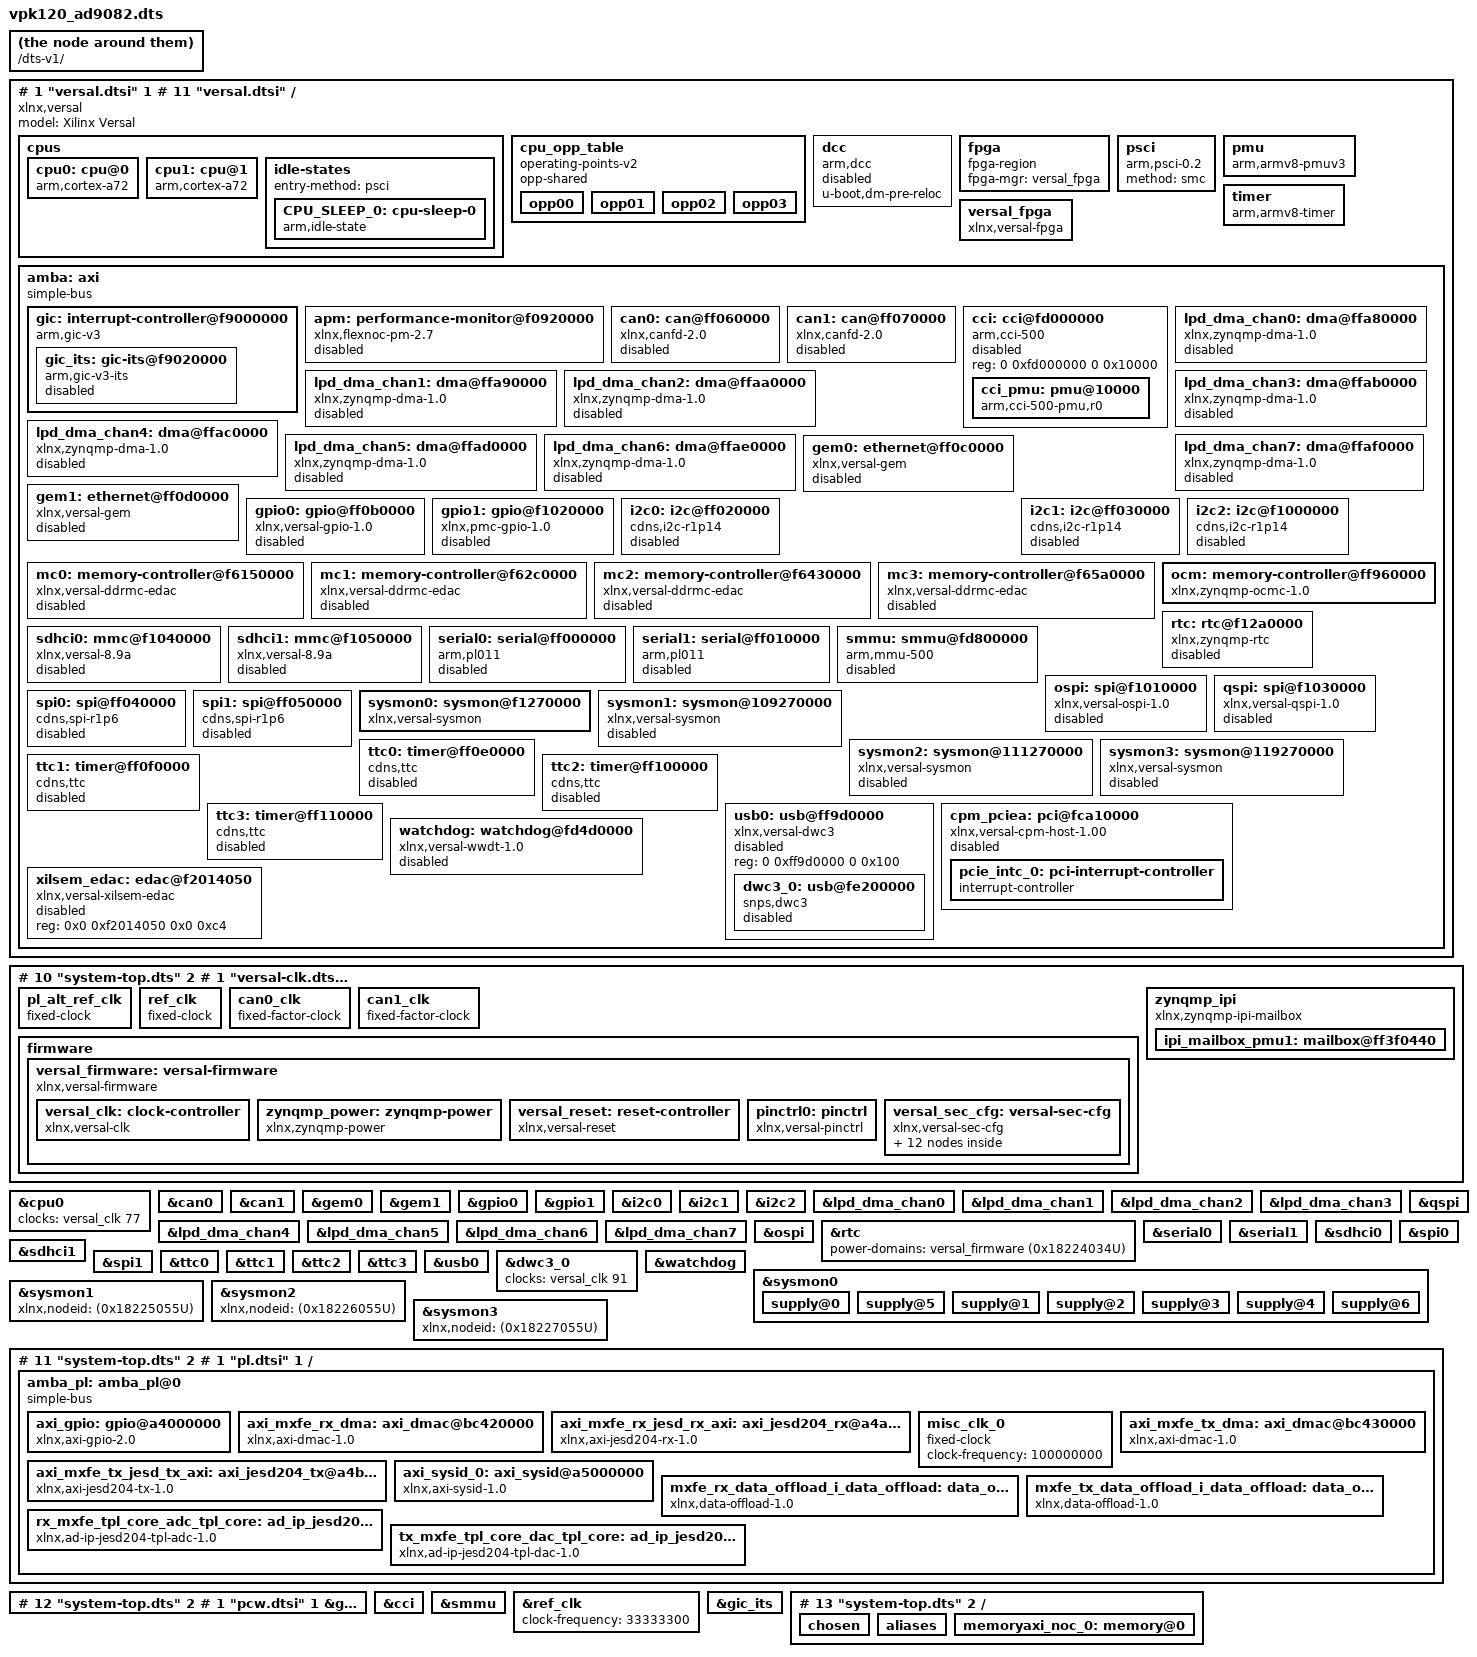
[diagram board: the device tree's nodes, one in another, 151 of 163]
# 0 "system-top.dts"
# 0 "<built-in>"
# 0 "<command-line>"
# 1 "system-top.dts"







/dts-v1/;
# 1 "versal.dtsi" 1
# 11 "versal.dtsi"
/ {
 compatible = "xlnx,versal";
 #address-cells = <2>;
 #size-cells = <2>;
 model = "Xilinx Versal";

 cpus: cpus {
  #address-cells = <1>;
  #size-cells = <0>;

  cpu0: cpu@0 {
   compatible = "arm,cortex-a72", "arm,armv8";
   device_type = "cpu";
   enable-method = "psci";
   operating-points-v2 = <&cpu_opp_table>;
   reg = <0>;
   cpu-idle-states = <&CPU_SLEEP_0>;
  };

  cpu1: cpu@1 {
   compatible = "arm,cortex-a72", "arm,armv8";
   device_type = "cpu";
   enable-method = "psci";
   operating-points-v2 = <&cpu_opp_table>;
   reg = <1>;
   cpu-idle-states = <&CPU_SLEEP_0>;
  };

  idle-states {
   entry-method = "psci";

   CPU_SLEEP_0: cpu-sleep-0 {
    compatible = "arm,idle-state";
    arm,psci-suspend-param = <0x40000000>;
    local-timer-stop;
    entry-latency-us = <300>;
    exit-latency-us = <600>;
    min-residency-us = <10000>;
   };
  };
 };

 cpu_opp_table: cpu_opp_table {
  compatible = "operating-points-v2";
  opp-shared;
  opp00 {
   opp-hz = /bits/ 64 <1199999988>;
   opp-microvolt = <1000000>;
   clock-latency-ns = <500000>;
  };
  opp01 {
   opp-hz = /bits/ 64 <599999994>;
   opp-microvolt = <1000000>;
   clock-latency-ns = <500000>;
  };
  opp02 {
   opp-hz = /bits/ 64 <399999996>;
   opp-microvolt = <1000000>;
   clock-latency-ns = <500000>;
  };
  opp03 {
   opp-hz = /bits/ 64 <299999997>;
   opp-microvolt = <1000000>;
   clock-latency-ns = <500000>;
  };
 };

 dcc: dcc {
  compatible = "arm,dcc";
  status = "disabled";
  u-boot,dm-pre-reloc;
 };

 fpga: fpga {
  compatible = "fpga-region";
  fpga-mgr = <&versal_fpga>;
  #address-cells = <2>;
  #size-cells = <2>;
 };

 psci: psci {
  compatible = "arm,psci-0.2";
  method = "smc";
 };

 pmu {
  compatible = "arm,armv8-pmuv3";
  interrupt-parent = <&gic>;
  interrupts = <1 7 0x304>;
 };

 timer: timer {
  compatible = "arm,armv8-timer";
  interrupt-parent = <&gic>;
  interrupts = <1 13 4>,
        <1 14 4>,
        <1 11 4>,
        <1 10 4>;
 };

 versal_fpga: versal_fpga {
  compatible = "xlnx,versal-fpga";
 };

 amba: axi {
  compatible = "simple-bus";
  #address-cells = <2>;
  #size-cells = <2>;
  ranges;
  interrupt-parent = <&gic>;
  u-boot,dm-pre-reloc;

  gic: interrupt-controller@f9000000 {
   compatible = "arm,gic-v3";
   #interrupt-cells = <3>;
   #address-cells = <2>;
   #size-cells = <2>;
   ranges;
   reg = <0 0xf9000000 0 0x80000>,
         <0 0xf9080000 0 0x80000>;
   interrupt-controller;
   interrupts = <1 9 4>;

   gic_its: gic-its@f9020000 {
    compatible = "arm,gic-v3-its";
    status = "disabled";
    msi-controller;
    msi-cells = <1>;
    reg = <0 0xf9020000 0 0x20000>;
   };
  };

  apm: performance-monitor@f0920000 {
   compatible = "xlnx,flexnoc-pm-2.7";
   status = "disabled";
   reg-names = "funnel", "baselpd", "basefpd";
   reg = <0x0 0xf0920000 0x0 0x1000>,
         <0x0 0xf0980000 0x0 0x9000>,
         <0x0 0xf0b80000 0x0 0x9000>;
  };

  can0: can@ff060000 {
   compatible = "xlnx,canfd-2.0";
   status = "disabled";
   reg = <0 0xff060000 0 0x6000>;
   interrupts = <0 20 4>;
   clock-names = "can_clk", "s_axi_aclk";
   rx-fifo-depth = <0x40>;
   tx-mailbox-count = <0x20>;
  };

  can1: can@ff070000 {
   compatible = "xlnx,canfd-2.0";
   status = "disabled";
   reg = <0 0xff070000 0 0x6000>;
   interrupts = <0 21 4>;
   clock-names = "can_clk", "s_axi_aclk";
   rx-fifo-depth = <0x40>;
   tx-mailbox-count = <0x20>;
  };

  cci: cci@fd000000 {
   compatible = "arm,cci-500";
   status = "disabled";
   reg = <0 0xfd000000 0 0x10000>;
   ranges = <0 0 0xfd000000 0xa0000>;
   #address-cells = <1>;
   #size-cells = <1>;
   cci_pmu: pmu@10000 {
    compatible = "arm,cci-500-pmu,r0";
    reg = <0x10000 0x90000>;
    interrupts = <0 106 4>,
          <0 106 4>,
          <0 106 4>,
          <0 106 4>,
          <0 106 4>,
          <0 106 4>,
          <0 106 4>,
          <0 106 4>,
          <0 106 4>;
   };
  };

  lpd_dma_chan0: dma@ffa80000 {
   compatible = "xlnx,zynqmp-dma-1.0";
   status = "disabled";
   reg = <0 0xffa80000 0 0x1000>;
   interrupts = <0 60 4>;
   clock-names = "clk_main", "clk_apb";

   xlnx,bus-width = <64>;

  };

  lpd_dma_chan1: dma@ffa90000 {
   compatible = "xlnx,zynqmp-dma-1.0";
   status = "disabled";
   reg = <0 0xffa90000 0 0x1000>;
   interrupts = <0 61 4>;
   clock-names = "clk_main", "clk_apb";

   xlnx,bus-width = <64>;

  };

  lpd_dma_chan2: dma@ffaa0000 {
   compatible = "xlnx,zynqmp-dma-1.0";
   status = "disabled";
   reg = <0 0xffaa0000 0 0x1000>;
   interrupts = <0 62 4>;
   clock-names = "clk_main", "clk_apb";

   xlnx,bus-width = <64>;

  };


  lpd_dma_chan3: dma@ffab0000 {
   compatible = "xlnx,zynqmp-dma-1.0";
   status = "disabled";
   reg = <0 0xffab0000 0 0x1000>;
   interrupts = <0 63 4>;
   clock-names = "clk_main", "clk_apb";

   xlnx,bus-width = <64>;

  };

  lpd_dma_chan4: dma@ffac0000 {
   compatible = "xlnx,zynqmp-dma-1.0";
   status = "disabled";
   reg = <0 0xffac0000 0 0x1000>;
   interrupts = <0 64 4>;
   clock-names = "clk_main", "clk_apb";

   xlnx,bus-width = <64>;

  };

  lpd_dma_chan5: dma@ffad0000 {
   compatible = "xlnx,zynqmp-dma-1.0";
   status = "disabled";
   reg = <0 0xffad0000 0 0x1000>;
   interrupts = <0 65 4>;
   clock-names = "clk_main", "clk_apb";

   xlnx,bus-width = <64>;

  };

  lpd_dma_chan6: dma@ffae0000 {
   compatible = "xlnx,zynqmp-dma-1.0";
   status = "disabled";
   reg = <0 0xffae0000 0 0x1000>;
   interrupts = <0 66 4>;
   clock-names = "clk_main", "clk_apb";

   xlnx,bus-width = <64>;

  };

  lpd_dma_chan7: dma@ffaf0000 {
   compatible = "xlnx,zynqmp-dma-1.0";
   status = "disabled";
   reg = <0 0xffaf0000 0 0x1000>;
   interrupts = <0 67 4>;
   clock-names = "clk_main", "clk_apb";

   xlnx,bus-width = <64>;

  };

  gem0: ethernet@ff0c0000 {
            compatible = "xlnx,versal-gem", "cdns,gem";
   status = "disabled";
   reg = <0 0xff0c0000 0 0x1000>;
   interrupts = <0 56 4>, <0 56 4>;
   clock-names = "pclk", "hclk", "tx_clk", "rx_clk", "tsu_clk";


   #address-cells = <1>;
   #size-cells = <0>;
  };

  gem1: ethernet@ff0d0000 {
            compatible = "xlnx,versal-gem", "cdns,gem";
   status = "disabled";
   reg = <0 0xff0d0000 0 0x1000>;
   interrupts = <0 58 4>, <0 58 4>;
   clock-names = "pclk", "hclk", "tx_clk", "rx_clk", "tsu_clk";


   #address-cells = <1>;
   #size-cells = <0>;
  };


  gpio0: gpio@ff0b0000 {
   compatible = "xlnx,versal-gpio-1.0";
   status = "disabled";
   reg = <0 0xff0b0000 0 0x1000>;
   interrupts = <0 13 4>;
   #gpio-cells = <2>;
   gpio-controller;
   #interrupt-cells = <2>;
   interrupt-controller;
  };

  gpio1: gpio@f1020000 {
   compatible = "xlnx,pmc-gpio-1.0";
   status = "disabled";
   reg = <0 0xf1020000 0 0x1000>;
   interrupts = <0 122 4>;
   #gpio-cells = <2>;
   gpio-controller;
   #interrupt-cells = <2>;
   interrupt-controller;
  };

  i2c0: i2c@ff020000 {
   compatible = "cdns,i2c-r1p14", "cdns,i2c-r1p10";
   status = "disabled";
   reg = <0 0xff020000 0 0x1000>;
   interrupts = <0 14 4>;
   clock-frequency = <100000>;
   #address-cells = <1>;
   #size-cells = <0>;
  };

  i2c1: i2c@ff030000 {
   compatible = "cdns,i2c-r1p14", "cdns,i2c-r1p10";
   status = "disabled";
   reg = <0 0xff030000 0 0x1000>;
   interrupts = <0 15 4>;
   clock-frequency = <100000>;
   #address-cells = <1>;
   #size-cells = <0>;
  };

  i2c2: i2c@f1000000 {
   compatible = "cdns,i2c-r1p14", "cdns,i2c-r1p10";
   status = "disabled";
   reg = <0 0xf1000000 0 0x1000>;
   interrupts = <0 123 4>;
   clock-frequency = <100000>;
   #address-cells = <1>;
   #size-cells = <0>;
  };

  mc0: memory-controller@f6150000 {
   compatible = "xlnx,versal-ddrmc-edac";
   status = "disabled";
   reg = <0x0 0xf6150000 0x0 0x2000>, <0x0 0xf6070000 0x0 0x20000>;
   reg-names = "ddrmc_base", "ddrmc_noc_base";
   interrupts = <0 147 4>;
   xlnx,mc-id = <0>;
  };

  mc1: memory-controller@f62c0000 {
   compatible = "xlnx,versal-ddrmc-edac";
   status = "disabled";
   reg = <0x0 0xf62c0000 0x0 0x2000>, <0x0 0xf6210000 0x0 0x20000>;
   reg-names = "ddrmc_base", "ddrmc_noc_base";
   interrupts = <0 147 4>;
   xlnx,mc-id = <1>;
  };

  mc2: memory-controller@f6430000 {
   compatible = "xlnx,versal-ddrmc-edac";
   status = "disabled";
   reg = <0x0 0xf6430000 0x0 0x2000>, <0x0 0xf6380000 0x0 0x20000>;
   reg-names = "ddrmc_base", "ddrmc_noc_base";
   interrupts = <0 147 4>;
   xlnx,mc-id = <2>;
  };

  mc3: memory-controller@f65a0000 {
   compatible = "xlnx,versal-ddrmc-edac";
   status = "disabled";
   reg = <0x0 0xf65a0000 0x0 0x2000>, <0x0 0xf64f0000 0x0 0x20000>;
   reg-names = "ddrmc_base", "ddrmc_noc_base";
   interrupts = <0 147 4>;
   xlnx,mc-id = <3>;
  };

  ocm: memory-controller@ff960000 {
   compatible = "xlnx,zynqmp-ocmc-1.0";
   reg = <0x0 0xff960000 0x0 0x1000>;
   interrupts = <0 10 4>;
  };

  rtc: rtc@f12a0000 {
   compatible = "xlnx,zynqmp-rtc";
   status = "disabled";
   reg = <0 0xf12a0000 0 0x100>;
   interrupt-names = "alarm", "sec";
   interrupts = <0 142 4>, <0 143 4>;
   calibration = <0x7FFF>;
  };

  sdhci0: mmc@f1040000 {
   compatible = "xlnx,versal-8.9a", "arasan,sdhci-8.9a";
   status = "disabled";
   reg = <0 0xf1040000 0 0x10000>;
   interrupts = <0 126 4>;
   clock-names = "clk_xin", "clk_ahb", "gate";
   #clock-cells = <1>;
   clock-output-names = "clk_out_sd0", "clk_in_sd0";


  };

  sdhci1: mmc@f1050000 {
   compatible = "xlnx,versal-8.9a", "arasan,sdhci-8.9a";
   status = "disabled";
   reg = <0 0xf1050000 0 0x10000>;
   interrupts = <0 128 4>;
   clock-names = "clk_xin", "clk_ahb", "gate";
   #clock-cells = <1>;
   clock-output-names = "clk_out_sd1", "clk_in_sd1";


  };

  serial0: serial@ff000000 {
   compatible = "arm,pl011", "arm,primecell";
   status = "disabled";
   reg = <0 0xff000000 0 0x1000>;
   interrupts = <0 18 4>;
   reg-io-width = <4>;
   clock-names = "uartclk", "apb_pclk";
   current-speed = <115200>;
   u-boot,dm-pre-reloc;
  };

  serial1: serial@ff010000 {
   compatible = "arm,pl011", "arm,primecell";
   status = "disabled";
   reg = <0 0xff010000 0 0x1000>;
   interrupts = <0 19 4>;
   reg-io-width = <4>;
   clock-names = "uartclk", "apb_pclk";
   current-speed = <115200>;
   u-boot,dm-pre-reloc;
  };

  smmu: smmu@fd800000 {
   compatible = "arm,mmu-500";
   status = "disabled";
   reg = <0 0xfd800000 0 0x40000>;
   stream-match-mask = <0x7c00>;
   #iommu-cells = <1>;
   #global-interrupts = <1>;
   interrupts = <0 107 4>,
         <0 107 4>, <0 107 4>, <0 107 4>, <0 107 4>,
         <0 107 4>, <0 107 4>, <0 107 4>, <0 107 4>,
         <0 107 4>, <0 107 4>, <0 107 4>, <0 107 4>,
         <0 107 4>, <0 107 4>, <0 107 4>, <0 107 4>,
         <0 107 4>, <0 107 4>, <0 107 4>, <0 107 4>,
         <0 107 4>, <0 107 4>, <0 107 4>, <0 107 4>,
         <0 107 4>, <0 107 4>, <0 107 4>, <0 107 4>,
         <0 107 4>, <0 107 4>, <0 107 4>, <0 107 4>;
  };

  ospi: spi@f1010000 {
   compatible = "xlnx,versal-ospi-1.0", "cadence,qspi", "cdns,qspi-nor";
   status = "disabled";
   reg = <0 0xf1010000 0 0x10000 0 0xc0000000 0 0x20000000>;
   interrupts = <0 124 4>, <0 124 4>;
   cdns,fifo-depth = <256>;
   cdns,fifo-width = <4>;
   cdns,is-dma = <1>;
   cdns,trigger-address = <0xC0000000>;
   #address-cells = <1>;
   #size-cells = <0>;
  };

  qspi: spi@f1030000 {
   compatible = "xlnx,versal-qspi-1.0";
   status = "disabled";
   reg = <0 0xf1030000 0 0x1000>;
   interrupts = <0 125 4>, <0 125 4>;
   clock-names = "ref_clk", "pclk";


   #address-cells = <1>;
   #size-cells = <0>;
  };


  spi0: spi@ff040000 {
   compatible = "cdns,spi-r1p6";
   status = "disabled";
   reg = <0 0xff040000 0 0x1000>;
   interrupts = <0 16 4>;
   clock-names = "ref_clk", "pclk";
   #address-cells = <1>;
   #size-cells = <0>;
  };

  spi1: spi@ff050000 {
   compatible = "cdns,spi-r1p6";
   status = "disabled";
   reg = <0 0xff050000 0 0x1000>;
   interrupts = <0 17 4>;
   clock-names = "ref_clk", "pclk";
   #address-cells = <1>;
   #size-cells = <0>;
  };

  sysmon0: sysmon@f1270000 {
   compatible = "xlnx,versal-sysmon";
   reg = <0x0 0xf1270000 0x0 0x4000>;
   interrupts = <0 144 4>;
   xlnx,numchannels = /bits/8 <0>;
  };

  sysmon1: sysmon@109270000 {
   compatible = "xlnx,versal-sysmon";
   #address-cells = <2>;
   #size-cells = <2>;
   status = "disabled";
   reg = <0x1 0x09270000 0x0 0x4000>;
   xlnx,numchannels = /bits/8 <0>;
  };

  sysmon2: sysmon@111270000 {
   compatible = "xlnx,versal-sysmon";
   #address-cells = <2>;
   #size-cells = <2>;
   status = "disabled";
   reg = <0x1 0x11270000 0x0 0x4000>;
   xlnx,numchannels = /bits/8 <0>;
  };

  sysmon3: sysmon@119270000 {
   compatible = "xlnx,versal-sysmon";
   #address-cells = <2>;
   #size-cells = <2>;
   status = "disabled";
   reg = <0x1 0x19270000 0x0 0x4000>;
   xlnx,numchannels = /bits/8 <0>;
  };

  ttc0: timer@ff0e0000 {
   compatible = "cdns,ttc";
   status = "disabled";
   interrupts = <0 37 4>, <0 38 4>, <0 39 4>;
   reg = <0x0 0xff0e0000 0x0 0x1000>;
   timer-width = <32>;
  };

  ttc1: timer@ff0f0000 {
   compatible = "cdns,ttc";
   status = "disabled";
   interrupts = <0 40 4>, <0 41 4>, <0 42 4>;
   reg = <0x0 0xff0f0000 0x0 0x1000>;
   timer-width = <32>;
  };

  ttc2: timer@ff100000 {
   compatible = "cdns,ttc";
   status = "disabled";
   interrupts = <0 43 4>, <0 44 4>, <0 45 4>;
   reg = <0x0 0xff100000 0x0 0x1000>;
   timer-width = <32>;
  };

  ttc3: timer@ff110000 {
   compatible = "cdns,ttc";
   status = "disabled";
   interrupts = <0 46 4>, <0 47 4>, <0 48 4>;
   reg = <0x0 0xff110000 0x0 0x1000>;
   timer-width = <32>;
  };

  usb0: usb@ff9d0000 {
   compatible = "xlnx,versal-dwc3";
   status = "disabled";
   reg = <0 0xff9d0000 0 0x100>;
   clock-names = "bus_clk", "ref_clk";
   ranges;
   #address-cells = <2>;
   #size-cells = <2>;

   dwc3_0: usb@fe200000 {
    compatible = "snps,dwc3";
    status = "disabled";
    reg = <0 0xfe200000 0 0x10000>;
    interrupt-names = "dwc_usb3", "otg", "usb-wakeup";
    interrupts = <0 0x16 4>, <0 0x1A 4>, <0x0 0x4a 0x4>;

    snps,dis_u2_susphy_quirk;
    snps,dis_u3_susphy_quirk;
    snps,quirk-frame-length-adjustment = <0x20>;
    clock-names = "ref";

   };
  };

  cpm_pciea: pci@fca10000 {
   #address-cells = <3>;
   #interrupt-cells = <1>;
   #size-cells = <2>;
   compatible = "xlnx,versal-cpm-host-1.00";
   status = "disabled";
   interrupt-map = <0 0 0 1 &pcie_intc_0 0>,
     <0 0 0 2 &pcie_intc_0 1>,
     <0 0 0 3 &pcie_intc_0 2>,
     <0 0 0 4 &pcie_intc_0 3>;
   interrupt-map-mask = <0 0 0 7>;
   interrupt-names = "misc";
   interrupts = <0 72 4>;
   ranges = <0x02000000 0x00000000 0xe0000000 0x0 0xe0000000 0x00000000 0x10000000>,
     <0x43000000 0x00000080 0x00000000 0x00000080 0x00000000 0x00000000 0x80000000>;
   msi-map = <0x0 &gic_its 0x0 0x10000>;
   reg = <0x0 0xfca10000 0x0 0x1000>,
         <0x6 0x00000000 0x0 0x1000000>;
   reg-names = "cpm_slcr", "cfg";
   pcie_intc_0: pci-interrupt-controller {
    #address-cells = <0>;
    #interrupt-cells = <1>;
    interrupt-controller ;
   };
  };

  watchdog: watchdog@fd4d0000 {
   compatible = "xlnx,versal-wwdt-1.0";
   status = "disabled";
   reg = <0 0xfd4d0000 0 0x10000>;
   interrupt-names = "wdt", "wwdt_reset_pending";
   interrupts = <0 0x64 1>, <0 0x6D 1>;
   timeout-sec = <30>;
   pretimeout-sec = <25>;
  };
  xilsem_edac: edac@f2014050 {
   compatible = "xlnx,versal-xilsem-edac";
   status = "disabled";
   reg = <0x0 0xf2014050 0x0 0xc4>;
  };
 };

};
# 10 "system-top.dts" 2
# 1 "versal-clk.dtsi" 1
# 10 "versal-clk.dtsi"
# 1 "include/dt-bindings/clock/xlnx-versal-clk.h" 1
# 11 "versal-clk.dtsi" 2
# 1 "include/dt-bindings/power/xlnx-versal-power.h" 1
# 12 "versal-clk.dtsi" 2
# 1 "include/dt-bindings/power/xlnx-versal-regnode.h" 1
# 13 "versal-clk.dtsi" 2
# 1 "include/dt-bindings/reset/xlnx-versal-resets.h" 1
# 14 "versal-clk.dtsi" 2
/ {
 pl_alt_ref_clk: pl_alt_ref_clk {
  u-boot,dm-pre-reloc;
  compatible = "fixed-clock";
  #clock-cells = <0>;
  clock-frequency = <33333333>;
 };

 ref_clk: ref_clk {
  u-boot,dm-pre-reloc;
  compatible = "fixed-clock";
  #clock-cells = <0>;
  clock-frequency = <33333333>;
 };

 can0_clk: can0_clk {
  #clock-cells = <0>;
  compatible = "fixed-factor-clock";
  clocks = <&versal_clk 96>;
  clock-div = <2>;
  clock-mult = <1>;
 };

 can1_clk: can1_clk {
  #clock-cells = <0>;
  compatible = "fixed-factor-clock";
  clocks = <&versal_clk 97>;
  clock-div = <2>;
  clock-mult = <1>;
 };

 firmware {
  versal_firmware: versal-firmware {
   compatible = "xlnx,versal-firmware";
   interrupt-parent = <&gic>;
   u-boot,dm-pre-reloc;
   method = "smc";
   #power-domain-cells = <1>;

   versal_clk: clock-controller {
    u-boot,dm-pre-reloc;
    #clock-cells = <1>;
    compatible = "xlnx,versal-clk";
    clocks = <&ref_clk>, <&pl_alt_ref_clk>;
    clock-names = "ref_clk", "pl_alt_ref_clk";
   };

   zynqmp_power: zynqmp-power {
    compatible = "xlnx,zynqmp-power";
    interrupt-parent = <&gic>;
    interrupts = <0 30 4>;
    mboxes = <&ipi_mailbox_pmu1 0>,
      <&ipi_mailbox_pmu1 1>;
    mbox-names = "tx", "rx";
   };
   versal_reset: reset-controller {
    compatible = "xlnx,versal-reset";
    #reset-cells = <1>;
   };

   pinctrl0: pinctrl {
    compatible = "xlnx,versal-pinctrl";
   };

   versal_sec_cfg: versal-sec-cfg {
    compatible = "xlnx,versal-sec-cfg";
    #address-cells = <1>;
    #size-cells = <1>;

    bbram_zeroize: bbram-zeroize@4 {
     reg = <0x04 0x4>;
    };

    bbram_key: bbram-key@10 {
     reg = <0x10 0x20>;
    };

    bbram_usr: bbram-usr@30 {
     reg = <0x30 0x4>;
    };

    bbram_lock: bbram-lock@48 {
     reg = <0x48 0x4>;
    };

    user_key0: user-key@110 {
     reg = <0x110 0x20>;
    };

    user_key1: user-key@130 {
     reg = <0x130 0x20>;
    };

    user_key2: user-key@150 {
     reg = <0x150 0x20>;
    };

    user_key3: user-key@170 {
     reg = <0x170 0x20>;
    };

    user_key4: user-key@190 {
     reg = <0x190 0x20>;
    };

    user_key5: user-key@1b0 {
     reg = <0x1b0 0x20>;
    };

    user_key6: user-key@1d0 {
     reg = <0x1d0 0x20>;
    };

    user_key7: user-key@1f0 {
     reg = <0x1f0 0x20>;
    };
   };
  };
 };

 zynqmp_ipi {
  compatible = "xlnx,zynqmp-ipi-mailbox";
  interrupt-parent = <&gic>;
  interrupts = <0 30 4>;
  xlnx,ipi-id = <2>;
  #address-cells = <2>;
  #size-cells = <2>;
  ranges;

  ipi_mailbox_pmu1: mailbox@ff3f0440 {
   reg = <0 0xff3f0440 0 0x20>,
         <0 0xff3f0460 0 0x20>,
         <0 0xff3f0280 0 0x20>,
         <0 0xff3f02a0 0 0x20>;
   reg-names = "local_request_region", "local_response_region",
        "remote_request_region", "remote_response_region";
   #mbox-cells = <1>;
   xlnx,ipi-id = <1>;
  };
 };
};

&cpu0 {
 clocks = <&versal_clk 77>;
};

&can0 {
 clocks = <&can0_clk>, <&versal_clk 82>;
 power-domains = <&versal_firmware (0x1822401fU)>;
};

&can1 {
 clocks = <&can1_clk>, <&versal_clk 82>;
 power-domains = <&versal_firmware (0x18224020U)>;
};

&gem0 {
 clocks = <&versal_clk 82>, <&versal_clk 88>, <&versal_clk 49>, <&versal_clk 48>, <&versal_clk 43>;
 power-domains = <&versal_firmware (0x18224019U)>;
};

&gem1 {
 clocks = <&versal_clk 82>, <&versal_clk 89>, <&versal_clk 51>, <&versal_clk 50>, <&versal_clk 43>;
 power-domains = <&versal_firmware (0x1822401aU)>;
};

&gpio0 {
 clocks = <&versal_clk 82>;
 power-domains = <&versal_firmware (0x18224023U)>;
};

&gpio1 {
 clocks = <&versal_clk 61>;
 power-domains = <&versal_firmware (0x1822402cU)>;
};

&i2c0 {
 clocks = <&versal_clk 98>;
 power-domains = <&versal_firmware (0x1822401dU)>;
};

&i2c1 {
 clocks = <&versal_clk 99>;
 power-domains = <&versal_firmware (0x1822401eU)>;
};

&i2c2 {
 clocks = <&versal_clk 62>;
 power-domains = <&versal_firmware (0x1822402dU)>;
};

&lpd_dma_chan0 {
 clocks = <&versal_clk 81>, <&versal_clk 82>;
 power-domains = <&versal_firmware (0x18224035U)>;
};

&lpd_dma_chan1 {
 clocks = <&versal_clk 81>, <&versal_clk 82>;
 power-domains = <&versal_firmware (0x18224036U)>;
};

&lpd_dma_chan2 {
 clocks = <&versal_clk 81>, <&versal_clk 82>;
 power-domains = <&versal_firmware (0x18224037U)>;
};

&lpd_dma_chan3 {
 clocks = <&versal_clk 81>, <&versal_clk 82>;
 power-domains = <&versal_firmware (0x18224038U)>;
};

&lpd_dma_chan4 {
 clocks = <&versal_clk 81>, <&versal_clk 82>;
 power-domains = <&versal_firmware (0x18224039U)>;
};

&lpd_dma_chan5 {
 clocks = <&versal_clk 81>, <&versal_clk 82>;
 power-domains = <&versal_firmware (0x1822403aU)>;
};

&lpd_dma_chan6 {
 clocks = <&versal_clk 81>, <&versal_clk 82>;
 power-domains = <&versal_firmware (0x1822403bU)>;
};

&lpd_dma_chan7 {
 clocks = <&versal_clk 81>, <&versal_clk 82>;
 power-domains = <&versal_firmware (0x1822403cU)>;
};

&qspi {
 clocks = <&versal_clk 57>, <&versal_clk 82>;
 power-domains = <&versal_firmware (0x1822402bU)>;
};

&ospi {
 clocks = <&versal_clk 58>;
 power-domains = <&versal_firmware (0x1822402aU)>;
 reset-names = "qspi";
 resets = <&versal_reset (0xc10402eU)>;
};

&rtc {
 power-domains = <&versal_firmware (0x18224034U)>;
};

&serial0 {
 clocks = <&versal_clk 92>, <&versal_clk 82>;
 power-domains = <&versal_firmware (0x18224021U)>;
};

&serial1 {
 clocks = <&versal_clk 93>, <&versal_clk 82>;
 power-domains = <&versal_firmware (0x18224022U)>;
};

&sdhci0 {
 clocks = <&versal_clk 59>, <&versal_clk 82>,
  <&versal_clk 74>;
 power-domains = <&versal_firmware (0x1822402eU)>;
};

&sdhci1 {
 clocks = <&versal_clk 60>, <&versal_clk 82>,
  <&versal_clk 74>;
 power-domains = <&versal_firmware (0x1822402fU)>;
};

&spi0 {
 clocks = <&versal_clk 94>, <&versal_clk 82>;
 power-domains = <&versal_firmware (0x1822401bU)>;
};

&spi1 {
 clocks = <&versal_clk 95>, <&versal_clk 82>;
 power-domains = <&versal_firmware (0x1822401cU)>;
};

&ttc0 {
 clocks = <&versal_clk 39>, <&versal_clk 82>;
 power-domains = <&versal_firmware (0x18224024U)>;
};

&ttc1 {
 clocks = <&versal_clk 40>, <&versal_clk 82>;
 power-domains = <&versal_firmware (0x18224025U)>;
};

&ttc2 {
 clocks = <&versal_clk 41>, <&versal_clk 82>;
 power-domains = <&versal_firmware (0x18224026U)>;
};

&ttc3 {
 clocks = <&versal_clk 42>, <&versal_clk 82>;
 power-domains = <&versal_firmware (0x18224027U)>;
};

&usb0 {
 clocks = <&versal_clk 91>, <&versal_clk 104>;
 power-domains = <&versal_firmware (0x18224018U)>;
 resets = <&versal_reset (0xc104036U)>;
};

&dwc3_0 {
 clocks = <&versal_clk 91>;
};

&watchdog {
 clocks = <&versal_clk 82>;
 power-domains = <&versal_firmware (0x18224029U)>;
};

&sysmon0 {
 xlnx,nodeid = <(0x18224055U)>;
};

&sysmon1 {
 xlnx,nodeid = <(0x18225055U)>;
};

&sysmon2 {
 xlnx,nodeid = <(0x18226055U)>;
};

&sysmon3 {
 xlnx,nodeid = <(0x18227055U)>;
};
# 11 "system-top.dts" 2
# 1 "pl.dtsi" 1







/ {
 amba_pl: amba_pl@0 {
  #address-cells = <2>;
  #size-cells = <2>;
  compatible = "simple-bus";
  ranges ;
  axi_gpio: gpio@a4000000 {
   #gpio-cells = <2>;
   #interrupt-cells = <2>;
   clock-names = "s_axi_aclk";
   clocks = <&versal_clk 65>;
   compatible = "xlnx,axi-gpio-2.0", "xlnx,xps-gpio-1.00.a";
   gpio-controller ;
   interrupt-controller ;
   interrupt-names = "ip2intc_irpt";
   interrupt-parent = <&gic>;
   interrupts = <0 84 4>;
   reg = <0x0 0xa4000000 0x0 0x1000>;
   xlnx,all-inputs = <0x0>;
   xlnx,all-inputs-2 = <0x0>;
   xlnx,all-outputs = <0x0>;
   xlnx,all-outputs-2 = <0x0>;
   xlnx,dout-default = <0x00000000>;
   xlnx,dout-default-2 = <0x00000000>;
   xlnx,gpio-width = <0x20>;
   xlnx,gpio2-width = <0x20>;
   xlnx,interrupt-present = <0x1>;
   xlnx,is-dual = <0x1>;
   xlnx,tri-default = <0xFFFFFFFF>;
   xlnx,tri-default-2 = <0xFFFFFFFF>;
  };
  axi_mxfe_rx_dma: axi_dmac@bc420000 {

   clock-names = "s_axi_aclk", "m_dest_axi_aclk", "s_axis_aclk";
   clocks = <&versal_clk 65>, <&versal_clk 66>, <&versal_clk 66>;
   compatible = "xlnx,axi-dmac-1.0";
   interrupt-names = "irq";
   interrupt-parent = <&gic>;
   interrupts = <0 97 4>;
   reg = <0x0 0xbc420000 0x0 0x1000>;
  };
  axi_mxfe_rx_jesd_rx_axi: axi_jesd204_rx@a4a90000 {

   clock-names = "s_axi_aclk", "core_clk";
   clocks = <&versal_clk 65>, <&misc_clk_0>;
   compatible = "xlnx,axi-jesd204-rx-1.0";
   interrupt-names = "irq";
   interrupt-parent = <&gic>;
   interrupts = <0 95 4>;
   reg = <0x0 0xa4a90000 0x0 0x4000>;
  };
  misc_clk_0: misc_clk_0 {
   #clock-cells = <0>;
   clock-frequency = <100000000>;
   compatible = "fixed-clock";
  };
  axi_mxfe_tx_dma: axi_dmac@bc430000 {

   clock-names = "s_axi_aclk", "m_src_axi_aclk", "m_axis_aclk";
   clocks = <&versal_clk 65>, <&versal_clk 66>, <&versal_clk 66>;
   compatible = "xlnx,axi-dmac-1.0";
   interrupt-names = "irq";
   interrupt-parent = <&gic>;
   interrupts = <0 96 4>;
   reg = <0x0 0xbc430000 0x0 0x1000>;
  };
  axi_mxfe_tx_jesd_tx_axi: axi_jesd204_tx@a4b90000 {

   clock-names = "s_axi_aclk", "core_clk";
   clocks = <&versal_clk 65>, <&misc_clk_0>;
   compatible = "xlnx,axi-jesd204-tx-1.0";
   interrupt-names = "irq";
   interrupt-parent = <&gic>;
   interrupts = <0 94 4>;
   reg = <0x0 0xa4b90000 0x0 0x4000>;
  };
  axi_sysid_0: axi_sysid@a5000000 {

   clock-names = "s_axi_aclk";
   clocks = <&versal_clk 65>;
   compatible = "xlnx,axi-sysid-1.0";
   reg = <0x0 0xa5000000 0x0 0x10000>;
  };
  mxfe_rx_data_offload_i_data_offload: data_offload@bc450000 {

   clock-names = "s_axi_aclk", "s_axis_aclk", "m_axis_aclk";
   clocks = <&versal_clk 65>, <&misc_clk_0>, <&versal_clk 66>;
   compatible = "xlnx,data-offload-1.0";
   reg = <0x0 0xbc450000 0x0 0x10000>;
  };
  mxfe_tx_data_offload_i_data_offload: data_offload@bc440000 {

   clock-names = "s_axi_aclk", "s_axis_aclk", "m_axis_aclk";
   clocks = <&versal_clk 65>, <&versal_clk 66>, <&misc_clk_0>;
   compatible = "xlnx,data-offload-1.0";
   reg = <0x0 0xbc440000 0x0 0x10000>;
  };
  rx_mxfe_tpl_core_adc_tpl_core: ad_ip_jesd204_tpl_adc@a4a10000 {

   clock-names = "link_clk", "s_axi_aclk";
   clocks = <&misc_clk_0>, <&versal_clk 65>;
   compatible = "xlnx,ad-ip-jesd204-tpl-adc-1.0";
   reg = <0x0 0xa4a10000 0x0 0x2000>;
  };
  tx_mxfe_tpl_core_dac_tpl_core: ad_ip_jesd204_tpl_dac@a4b10000 {

   clock-names = "link_clk", "s_axi_aclk";
   clocks = <&misc_clk_0>, <&versal_clk 65>;
   compatible = "xlnx,ad-ip-jesd204-tpl-dac-1.0";
   reg = <0x0 0xa4b10000 0x0 0x2000>;
  };
 };
};
# 12 "system-top.dts" 2
# 1 "pcw.dtsi" 1







&gic {
 num_cpus = <2>;
 num_interrupts = <96>;
};
&lpd_dma_chan0 {
 status = "okay";
};
&lpd_dma_chan1 {
 status = "okay";
};
&lpd_dma_chan2 {
 status = "okay";
};
&lpd_dma_chan3 {
 status = "okay";
};
&lpd_dma_chan4 {
 status = "okay";
};
&lpd_dma_chan5 {
 status = "okay";
};
&lpd_dma_chan6 {
 status = "okay";
};
&lpd_dma_chan7 {
 status = "okay";
};
&gem0 {
 phy-mode = "rgmii-id";
 status = "okay";
};
&cci {
 status = "okay";
};
&smmu {
 status = "okay";
};
&i2c0 {
 clock-frequency = <400000>;
 status = "okay";
};
&i2c1 {
 clock-frequency = <400000>;
 status = "okay";
};
&gpio1 {
 status = "okay";
};
&qspi {
 is-dual = <1>;
 num-cs = <2>;
 spi-rx-bus-width = <4>;
 spi-tx-bus-width = <4>;
 status = "okay";
};
&rtc {
 status = "okay";
};
&sdhci1 {
 clock-frequency = <199999802>;
 status = "okay";
 xlnx,mio-bank = <0x1>;
};
&sysmon0 {
 #address-cells = <2>;
 #size-cells = <2>;
 xlnx,num-of-slr = <1>;
 xlnx,numchannels = /bits/8 <7>;
 xlnx,ssit-device = <0x0>;
 supply@0 {
  reg = <0>;
  xlnx,name = "vccaux";
 };
 supply@5 {
  reg = <5>;
  xlnx,name = "vcc_soc";
 };
 supply@1 {
  reg = <1>;
  xlnx,name = "vccaux_pmc";
 };
 supply@2 {
  reg = <2>;
  xlnx,name = "vcc_pmc";
 };
 supply@3 {
  reg = <3>;
  xlnx,name = "vcc_psfp";
 };
 supply@4 {
  reg = <4>;
  xlnx,name = "vcc_pslp";
 };
 supply@6 {
  reg = <6>;
  xlnx,name = "vp_vn";
 };
};
&serial0 {
 cts-override ;
 current-speed = <115200>;
 device_type = "serial";
 port-number = <0>;
 status = "okay";
};
&spi0 {
 is-decoded-cs = <0>;
 num-cs = <3>;
 status = "okay";
};
&spi1 {
 is-decoded-cs = <0>;
 num-cs = <3>;
 status = "okay";
};
&usb0 {
 status = "okay";
};
&dwc3_0 {
 status = "okay";
};
&ref_clk {
 clock-frequency = <33333300>;
};
&gic_its {
 status = "okay";
};
# 13 "system-top.dts" 2
/ {
 chosen {
 };
 aliases {
  ethernet0 = &gem0;
  i2c0 = &i2c0;
  i2c1 = &i2c1;
  serial0 = &serial0;
  spi0 = &qspi;
  spi1 = &spi0;
  spi2 = &spi1;
 };
 memoryaxi_noc_0: memory@0 {
  device_type = "memory";
  reg = <0x0 0x00000000 0x0 0x80000000>, <0x00000008 0x00000000 0x0 0x80000000>;
 };
};
